# km_csr: IP-XACT component
VLNV tenstorrent.com:ocah:km_csr:1.0

## Address spaces and blocks
km_csr_mmap.km_csr: base 'h0, range 'h4c0, width 32

## Registers
Registers are 32-bit, read-only, no defined reset value unless marked. A register's access mark holds for its fields unless they carry their own. Offsets are from the block's base; lines under a group give offsets from that group; [hi:lo] are bit positions; {n}, {i} and the like mark numbered series; 'fields as' and 'values as' point back to an identical list; <NAME> marks a mode.

## km_csr_mmap.km_csr — Control and status registers for the Key Manager subsystem
Base 0x00000000
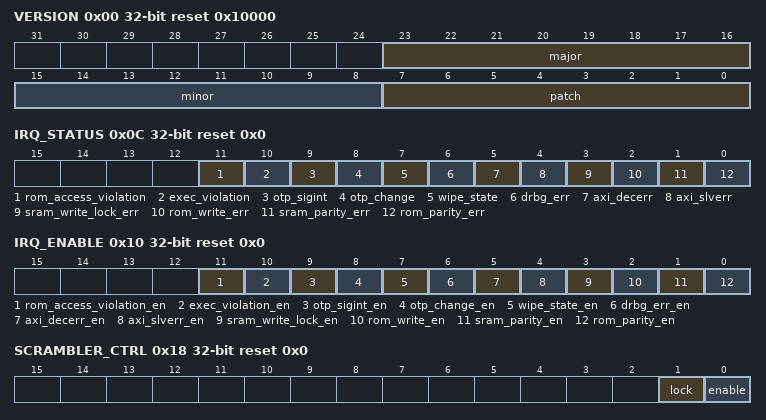
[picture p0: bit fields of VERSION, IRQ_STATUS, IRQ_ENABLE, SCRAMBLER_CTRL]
0x00 VERSION reset 0x10000 — Hardware version register (semantic versioning: major.minor.patch)
  [23:16] major — Major version number
  [15:8] minor — Minor version number
  [7:0] patch — Patch version number
0x04 CTRL reset 0x0 — Control register (reserved for future use)
0x08 SOFT_RST_CODE rw reset 0x0 — Software reset code register. Write 0x53525354 ('SRST') to trigger soft reset. Any other value has no effect.
  [31:0] code — 32-bit reset code. Write 0x53525354 to trigger soft reset.
0x0C IRQ_STATUS access per field reset 0x0 — Interrupt status register. Sticky bits cleared by writing 1.
  [11] rom_access_violation rw write-1-clears — KM ROM instruction fetch or data read attempted after the ROM lockout engaged. The lockout engages on the first committed instruction fetch from write-locked SRAM once SRAM_EXEC_MODE.enable is set, and clears only on warm or cold reset. Sticky, write 1 to clear.
  [10] exec_violation rw write-1-clears — Instruction fetch from a non-whitelisted (non-executable) memory region detected, excluding the KM ROM. Sticky, write 1 to clear.
  [9] otp_sigint rw write-1-clears — OTP dual-rail encoding integrity violation: value and complement are not complementary on at least one field. Sticky, write 1 to clear.
  [8] otp_change rw write-1-clears — An OTP readout field value changed (decoded value differs from prior cycle). Sticky, write 1 to clear. Check OTP_CHANGE_STATUS for the specific field(s).
  [7] wipe_state rw write-1-clears — Wipe state event (rising edge of wipe_state input). Sticky, write 1 to clear.
  [6] drbg_err rw write-1-clears — DRBG Sampler error (timeout or AXI-Stream error). Sticky, write 1 to clear.
  [5] axi_decerr rw write-1-clears — AXI DECERR (decode error) response detected on CPU bus transaction. Sticky, write 1 to clear.
  [4] axi_slverr rw write-1-clears — AXI SLVERR (slave error) response detected on CPU bus transaction. Sticky, write 1 to clear.
  [3] sram_write_lock_err rw write-1-clears — SRAM write attempt to a write-locked region detected. Sticky, write 1 to clear.
  [2] rom_write_err rw write-1-clears — ROM write attempt detected (ROM is read-only). Sticky, write 1 to clear.
  [1] sram_parity_err rw write-1-clears — SRAM parity error detected. Sticky, write 1 to clear.
  [0] rom_parity_err rw write-1-clears — ROM parity error detected. Sticky, write 1 to clear.
0x10 IRQ_ENABLE access per field reset 0x0 — Interrupt enable/mask register
  [11] rom_access_violation_en rw — Enable ROM lockout violation interrupt
  [10] exec_violation_en rw — Enable execute-permission whitelist violation interrupt
  [9] otp_sigint_en rw — Enable OTP dual-rail integrity violation interrupt
  [8] otp_change_en rw — Enable OTP field change interrupt
  [7] wipe_state_en rw — Enable wipe state interrupt
  [6] drbg_err_en rw — Enable DRBG Sampler error interrupt
  [5] axi_decerr_en rw — Enable AXI DECERR error interrupt
  [4] axi_slverr_en rw — Enable AXI SLVERR error interrupt
  [3] sram_write_lock_en rw — Enable SRAM write-lock violation interrupt
  [2] rom_write_en rw — Enable ROM write error interrupt
  [1] sram_parity_en rw — Enable SRAM parity error interrupt
  [0] rom_parity_en rw — Enable ROM parity error interrupt
0x14 SCRAMBLER_KEY rw — 32-bit scrambler key for SRAM address/data scrambling. When locked: writes ignored, reads return 0. No reset; powers up random.
  [31:0] key — Scrambler key value. Not readable when SCRAMBLER_CTRL.LOCK=1 (returns 0). No reset for security; power-up value undefined.
0x18 SCRAMBLER_CTRL access per field reset 0x0 — Scrambler control register
  [1] lock rw — Lock scrambler key and enable bit. Once set, key and enable cannot be modified until reset. Write-once (0->1 only). Security requirement: prevents disabling scrambling after key provisioning.
  [0] enable rw — Enable SRAM scrambling. When 0, data passes through unmodified. Locked when LOCK=1 (security requirement).
0x1C SRAM_LOCK rw reset 0x0 — SRAM write-lock bits. Bit[i]=1 locks region i (1 KB each, 32 regions). Write-1-only: writing 1 sets the bit, writing 0 has no effect. Cleared by warm or cold reset (warm reset domain); ROM re-applies the lock policy on every boot before handover to mutable firmware.
  [31:0] lock_bits write-1-sets — One bit per 1 KB SRAM region. Region 0 = 0x8000-0x83FF, region 31 = 0xFC00-0xFFFF. Write 1 to lock; 0 has no effect. Warm reset domain: cleared by warm or cold reset.
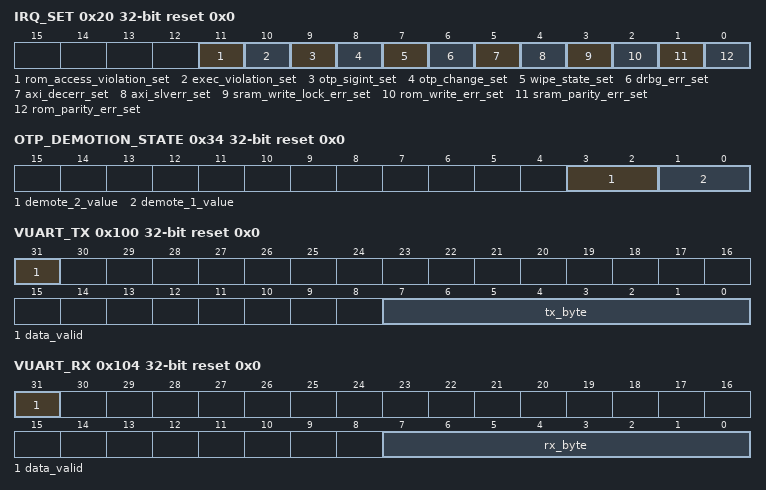
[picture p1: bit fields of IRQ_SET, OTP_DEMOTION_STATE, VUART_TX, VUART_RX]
0x20 IRQ_SET wo reset 0x0 — Interrupt set register. Write 1 to trigger corresponding interrupt (for ISR testing). Write-only, reads return 0.
  [11] rom_access_violation_set — Write 1 to set IRQ_STATUS.ROM_ACCESS_VIOLATION (triggers ROM lockout violation interrupt for testing)
  [10] exec_violation_set — Write 1 to set IRQ_STATUS.EXEC_VIOLATION (triggers exec-permission violation interrupt for testing)
  [9] otp_sigint_set — Write 1 to set IRQ_STATUS.OTP_SIGINT (triggers OTP sigint interrupt for testing)
  [8] otp_change_set — Write 1 to set IRQ_STATUS.OTP_CHANGE (triggers OTP change interrupt for testing)
  [7] wipe_state_set — Write 1 to set IRQ_STATUS.WIPE_STATE (triggers wipe state interrupt for testing)
  [6] drbg_err_set — Write 1 to set IRQ_STATUS.DRBG_ERR (triggers DRBG Sampler interrupt for testing)
  [5] axi_decerr_set — Write 1 to set IRQ_STATUS.AXI_DECERR (triggers AXI DECERR interrupt for testing)
  [4] axi_slverr_set — Write 1 to set IRQ_STATUS.AXI_SLVERR (triggers AXI SLVERR interrupt for testing)
  [3] sram_write_lock_err_set — Write 1 to set IRQ_STATUS.SRAM_WRITE_LOCK_ERR (triggers SRAM write-lock interrupt for testing)
  [2] rom_write_err_set — Write 1 to set IRQ_STATUS.ROM_WRITE_ERR (triggers ROM write interrupt for testing)
  [1] sram_parity_err_set — Write 1 to set IRQ_STATUS.SRAM_PARITY_ERR (triggers SRAM parity interrupt for testing)
  [0] rom_parity_err_set — Write 1 to set IRQ_STATUS.ROM_PARITY_ERR (triggers ROM parity interrupt for testing)
0x24 SRAM_WRITE_LOCK_VIOLATION rw reset 0x0 — Which SRAM region(s) had write attempts while locked. Bit[i]=region i. Sticky, write 1 to clear each bit.
  [31:0] violation_bits write-1-clears — Bit[i]=1 if region i had attempted write while locked. Sticky, write 1 to clear each bit.
0x28 RECOVERABLE_ERR access per field reset 0x0 — Recoverable error status. Firmware writes 1 to set (after recovering in ISR), writes 0 to clear (e.g. when SEP requests clear). Drives recoverable error event output.
  [0] recoverable_err rw — 1 = recoverable fault occurred and was handled by ISR; 0 = clear. Write 1 to set, write 0 to clear.
0x2C BOOT_STATUS access per field reset 0x0 — Boot status. Firmware writes 1 to COLD_BOOT_DONE after cold-boot init completes; bit remains set until next cold reset.
  [0] cold_boot_done rw write-1-sets — Write-1-only: set by ROM firmware at end of cold boot. Reads 0 after cold reset; reads 1 after firmware sets it. Sticky until next cold reset (preserved across warm resets).
0x30 OTP_LIFE_CYCLE reset 0x0 (reset mask 0xFFFFFF00) — Life cycle state. 8-bit (4-bit value differentially encoded). Read-through from OTP port; no reset.
  [7:0] value — 8-bit life cycle state from OTP. No reset; power-up value undefined.
0x34 OTP_DEMOTION_STATE reset 0x0 (reset mask 0xFFFFFFF0) — Demotion state. 2-bit, differentially encoded. Read-through from OTP port; no reset.
  [3:2] demote_2_value — 2-bit demotion 2 state from OTP. No reset; power-up value undefined.
  [1:0] demote_1_value — 2-bit demotion 1 state from OTP. No reset; power-up value undefined.
0x38 SRAM_EXEC_MODE access per field reset 0x0 — Execute-permission whitelist mode. Write-1-only (woset); cleared by warm or cold reset. 0=ROM executable; 1=write-locked SRAM regions executable, and the ROM lockout is armed. Set by ROM stack-less handover immediately before jumping to mutable firmware.
  [0] enable rw write-1-sets — Execute-permission mode: 0=ROM-only whitelist; 1=write-locked SRAM whitelist, arming the ROM lockout. Write 1 to set; write 0 has no effect. Warm reset domain: cleared by warm or cold reset.
0xB8 IRQ_ENTRY_ADDR rw reset 0x10 — Effective IRQ entry address for subsequent interrupts. Writable while unlocked; any 32-bit value accepted.
  [31:0] addr — IRQ handler entry PC. Reset matches ROM vector at 0x10. When locked, SW writes do not update storage.
0xBC IRQ_ENTRY_LOCK access per field reset 0x0 — Write-one-only lock for IRQ_ENTRY_ADDR. Separate readable register; cleared only on KM reset.
  [0] lock rw write-1-sets — Write 1 to set; write 0 has no effect; sticky until reset.
0x100 VUART_TX access per field reset 0x0 — Virtual UART transmit register. Write a byte to send to testbench. DATA_VALID is set on write and self-clears.
  [31] data_valid rw — Data valid strobe. Set by firmware on write, cleared by hardware after one cycle.
  [7:0] tx_byte rw — Byte to transmit (write to send character to testbench)
0x104 VUART_RX reset 0x0 — Virtual UART receive register. Testbench writes bytes here for firmware to read.
  [31] data_valid — RX data valid. Set by testbench, cleared by firmware read.
  [7:0] rx_byte — Received byte from testbench
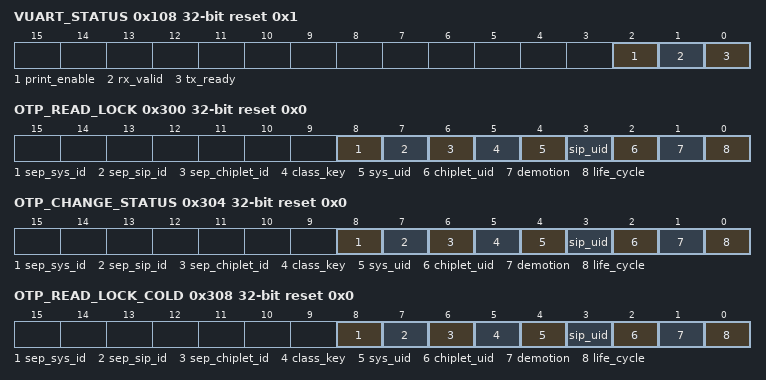
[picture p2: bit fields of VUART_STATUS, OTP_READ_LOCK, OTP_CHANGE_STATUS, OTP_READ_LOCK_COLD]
0x108 VUART_STATUS reset 0x1 — Virtual UART status register for flow control
  [2] print_enable — Enable VUART printing. Set by testbench to enable printf output. Disabled by default to save simulation time.
  [1] rx_valid — RX has valid data available
  [0] tx_ready — TX ready to accept data (always 1 in simulation)
0x110 TB_RESULT rw reset 0x0 — Test result register. Firmware writes 0=fail, 1=pass.
  [31:0] result — Test result: 0=fail, 1=pass
0x114 TB_SIGNATURE rw reset 0x0 — Test completion signature. Firmware writes 0x600D600D (pass) or 0xBADBADBA (fail).
  [31:0] signature — Completion signature value
0x118 TB_ERRCODE rw reset 0x0 — Test error code register. Firmware writes optional error code for debugging.
  [31:0] errcode — Error code value
0x11C TB_SUBTEST rw reset 0x0 — Current subtest number register. Firmware increments for each subtest.
  [31:0] subtest — Current subtest number
0x120 TB_CMD rw reset 0x0 — Testbench command register. Firmware writes command, testbench reads and clears.
  [31:0] cmd — Command code (0=NOP, 1=ROM_PARITY_EN, 2=ROM_PARITY_DIS, 3=SRAM_PARITY_EN, 4=SRAM_PARITY_DIS)
0x124 TB_CMD_ARG rw reset 0x0 — Testbench command argument register. Firmware writes optional argument.
  [31:0] arg — Command argument value
0x128 TB_CMD_STATUS rw reset 0x0 — Testbench command status register. Testbench writes status, firmware reads.
  [31:0] status — Command status: 0=IDLE, 1=ACK, 0xFFFFFFFF=ERR
0x12C TB_CMD_RESULT reset 0x0 — Testbench command result register. Testbench writes result value.
  [31:0] result — Command result value
0x1FC DEBUG reset 0xCAFEBEEF — Debug register with known constant value for verification
  [31:0] magic — Magic constant: 0xCAFEBEEF
{0x200+4i} OTP_CHIPLET_UID_VAL_{i} (i=0..7) — Dual-rail OTP readout word (value or complement half). Read-through from OTP port; no reset. Returns zero when the field's bit is set in either OTP_READ_LOCK or OTP_READ_LOCK_COLD.
  [31:0] value — 32-bit OTP word. No reset; power-up value undefined.
{0x220+4i} OTP_CHIPLET_UID_CPL_{i} (i=0..7) — Dual-rail OTP readout word (value or complement half). Read-through from OTP port; no reset. Returns zero when the field's bit is set in either OTP_READ_LOCK or OTP_READ_LOCK_COLD.
  [31:0] value — 32-bit OTP word. No reset; power-up value undefined.
{0x240+4i} OTP_SIP_UID_VAL_{i} (i=0..7) — Dual-rail OTP readout word (value or complement half). Read-through from OTP port; no reset. Returns zero when the field's bit is set in either OTP_READ_LOCK or OTP_READ_LOCK_COLD.
  [31:0] value — 32-bit OTP word. No reset; power-up value undefined.
{0x260+4i} OTP_SIP_UID_CPL_{i} (i=0..7) — Dual-rail OTP readout word (value or complement half). Read-through from OTP port; no reset. Returns zero when the field's bit is set in either OTP_READ_LOCK or OTP_READ_LOCK_COLD.
  [31:0] value — 32-bit OTP word. No reset; power-up value undefined.
{0x280+4i} OTP_SYS_UID_VAL_{i} (i=0..7) — Dual-rail OTP readout word (value or complement half). Read-through from OTP port; no reset. Returns zero when the field's bit is set in either OTP_READ_LOCK or OTP_READ_LOCK_COLD.
  [31:0] value — 32-bit OTP word. No reset; power-up value undefined.
{0x2A0+4i} OTP_SYS_UID_CPL_{i} (i=0..7) — Dual-rail OTP readout word (value or complement half). Read-through from OTP port; no reset. Returns zero when the field's bit is set in either OTP_READ_LOCK or OTP_READ_LOCK_COLD.
  [31:0] value — 32-bit OTP word. No reset; power-up value undefined.
{0x2C0+4i} OTP_CLASS_KEY_VAL_{i} (i=0..7) — Dual-rail OTP readout word (value or complement half). Read-through from OTP port; no reset. Returns zero when the field's bit is set in either OTP_READ_LOCK or OTP_READ_LOCK_COLD.
  [31:0] value — 32-bit OTP word. No reset; power-up value undefined.
{0x2E0+4i} OTP_CLASS_KEY_CPL_{i} (i=0..7) — Dual-rail OTP readout word (value or complement half). Read-through from OTP port; no reset. Returns zero when the field's bit is set in either OTP_READ_LOCK or OTP_READ_LOCK_COLD.
  [31:0] value — 32-bit OTP word. No reset; power-up value undefined.
0x300 OTP_READ_LOCK access per field reset 0x0 — OTP field warm-reset-domain read-lock bits. Write 1 to set; writing 0 has no effect. Locked reads of the corresponding OTP field return zero (effective lock = OTP_READ_LOCK | OTP_READ_LOCK_COLD). Warm-reset domain: cleared by warm or cold reset.
  [8] sep_sys_id rw write-1-sets — Lock OTP_SEP_SYS_ID_VAL/CPL reads (returns zero when locked)
  [7] sep_sip_id rw write-1-sets — Lock OTP_SEP_SIP_ID_VAL/CPL reads (returns zero when locked)
  [6] sep_chiplet_id rw write-1-sets — Lock OTP_SEP_CHIPLET_ID_VAL/CPL reads (returns zero when locked)
  [5] class_key rw write-1-sets — Lock OTP_CLASS_KEY_VAL/CPL reads (returns zero when locked)
  [4] sys_uid rw write-1-sets — Lock OTP_SYS_UID_VAL/CPL reads (returns zero when locked)
  [3] sip_uid rw write-1-sets — Lock OTP_SIP_UID_VAL/CPL reads (returns zero when locked)
  [2] chiplet_uid rw write-1-sets — Lock OTP_CHIPLET_UID_VAL/CPL reads (returns zero when locked)
  [1] demotion rw write-1-sets — Lock OTP_DEMOTION_STATE reads (returns zero when locked)
  [0] life_cycle rw write-1-sets — Lock OTP_LIFE_CYCLE reads (returns zero when locked)
0x304 OTP_CHANGE_STATUS access per field reset 0x0 — OTP field change status. A bit is set when the corresponding field's decoded value changes. Sticky, write 1 to clear. Valid after IRQ_STATUS.OTP_CHANGE fires.
  [8] sep_sys_id rw write-1-clears — OTP_SEP_SYS_ID value changed since last cycle. Sticky, write 1 to clear.
  [7] sep_sip_id rw write-1-clears — OTP_SEP_SIP_ID value changed since last cycle. Sticky, write 1 to clear.
  [6] sep_chiplet_id rw write-1-clears — OTP_SEP_CHIPLET_ID value changed since last cycle. Sticky, write 1 to clear.
  [5] class_key rw write-1-clears — OTP_CLASS_KEY value changed since last cycle. Sticky, write 1 to clear.
  [4] sys_uid rw write-1-clears — OTP_SYS_UID value changed since last cycle. Sticky, write 1 to clear.
  [3] sip_uid rw write-1-clears — OTP_SIP_UID value changed since last cycle. Sticky, write 1 to clear.
  [2] chiplet_uid rw write-1-clears — OTP_CHIPLET_UID value changed since last cycle. Sticky, write 1 to clear.
  [1] demotion rw write-1-clears — OTP_DEMOTION_STATE value changed since last cycle. Sticky, write 1 to clear.
  [0] life_cycle rw write-1-clears — OTP_LIFE_CYCLE value changed since last cycle. Sticky, write 1 to clear.
0x308 OTP_READ_LOCK_COLD access per field reset 0x0 — OTP field cold-reset-domain read-lock bits. Write 1 to set; writing 0 has no effect. Locked reads of the corresponding OTP field return zero (effective lock = OTP_READ_LOCK | OTP_READ_LOCK_COLD). Cold-reset domain: survives warm reset.
  [8] sep_sys_id rw write-1-sets — Cold-reset read-lock for OTP_SEP_SYS_ID_VAL/CPL. Effective lock = OTP_READ_LOCK.sep_sys_id | OTP_READ_LOCK_COLD.sep_sys_id.
  [7] sep_sip_id rw write-1-sets — Cold-reset read-lock for OTP_SEP_SIP_ID_VAL/CPL. Effective lock = OTP_READ_LOCK.sep_sip_id | OTP_READ_LOCK_COLD.sep_sip_id.
  [6] sep_chiplet_id rw write-1-sets — Cold-reset read-lock for OTP_SEP_CHIPLET_ID_VAL/CPL. Effective lock = OTP_READ_LOCK.sep_chiplet_id | OTP_READ_LOCK_COLD.sep_chiplet_id.
  [5] class_key rw write-1-sets — Cold-reset read-lock for OTP_CLASS_KEY_VAL/CPL. Effective lock = OTP_READ_LOCK.class_key | OTP_READ_LOCK_COLD.class_key.
  [4] sys_uid rw write-1-sets — Cold-reset read-lock for OTP_SYS_UID_VAL/CPL. Effective lock = OTP_READ_LOCK.sys_uid | OTP_READ_LOCK_COLD.sys_uid.
  [3] sip_uid rw write-1-sets — Cold-reset read-lock for OTP_SIP_UID_VAL/CPL. Effective lock = OTP_READ_LOCK.sip_uid | OTP_READ_LOCK_COLD.sip_uid.
  [2] chiplet_uid rw write-1-sets — Cold-reset read-lock for OTP_CHIPLET_UID_VAL/CPL. Effective lock = OTP_READ_LOCK.chiplet_uid | OTP_READ_LOCK_COLD.chiplet_uid.
  [1] demotion rw write-1-sets — Cold-reset read-lock for OTP_DEMOTION_STATE. Effective lock = OTP_READ_LOCK.demotion | OTP_READ_LOCK_COLD.demotion.
  [0] life_cycle rw write-1-sets — Cold-reset read-lock for OTP_LIFE_CYCLE. Effective lock = OTP_READ_LOCK.life_cycle | OTP_READ_LOCK_COLD.life_cycle.
{0x400+4i} OTP_SEP_CHIPLET_ID_VAL_{i} (i=0..7) — Dual-rail OTP readout word (value or complement half). Read-through from OTP port; no reset. Returns zero when the field's bit is set in either OTP_READ_LOCK or OTP_READ_LOCK_COLD.
  [31:0] value — 32-bit OTP word. No reset; power-up value undefined.
{0x420+4i} OTP_SEP_CHIPLET_ID_CPL_{i} (i=0..7) — Dual-rail OTP readout word (value or complement half). Read-through from OTP port; no reset. Returns zero when the field's bit is set in either OTP_READ_LOCK or OTP_READ_LOCK_COLD.
  [31:0] value — 32-bit OTP word. No reset; power-up value undefined.
{0x440+4i} OTP_SEP_SIP_ID_VAL_{i} (i=0..7) — Dual-rail OTP readout word (value or complement half). Read-through from OTP port; no reset. Returns zero when the field's bit is set in either OTP_READ_LOCK or OTP_READ_LOCK_COLD.
  [31:0] value — 32-bit OTP word. No reset; power-up value undefined.
{0x460+4i} OTP_SEP_SIP_ID_CPL_{i} (i=0..7) — Dual-rail OTP readout word (value or complement half). Read-through from OTP port; no reset. Returns zero when the field's bit is set in either OTP_READ_LOCK or OTP_READ_LOCK_COLD.
  [31:0] value — 32-bit OTP word. No reset; power-up value undefined.
{0x480+4i} OTP_SEP_SYS_ID_VAL_{i} (i=0..7) — Dual-rail OTP readout word (value or complement half). Read-through from OTP port; no reset. Returns zero when the field's bit is set in either OTP_READ_LOCK or OTP_READ_LOCK_COLD.
  [31:0] value — 32-bit OTP word. No reset; power-up value undefined.
{0x4A0+4i} OTP_SEP_SYS_ID_CPL_{i} (i=0..7) — Dual-rail OTP readout word (value or complement half). Read-through from OTP port; no reset. Returns zero when the field's bit is set in either OTP_READ_LOCK or OTP_READ_LOCK_COLD.
  [31:0] value — 32-bit OTP word. No reset; power-up value undefined.

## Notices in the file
SPDX-License-Identifier: Apache-2.0
SPDX-FileCopyrightText: 2026 Tenstorrent USA, Inc.
